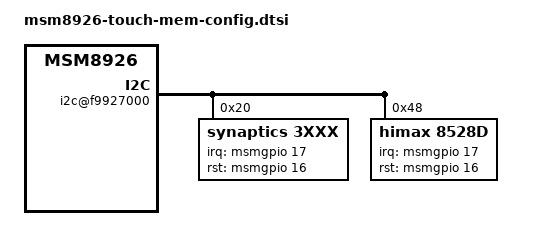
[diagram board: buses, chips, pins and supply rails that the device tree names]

/* Copyright (c) 2013, The Linux Foundation. All rights reserved.
 *
 * This program is free software; you can redistribute it and/or modify
 * it under the terms of the GNU General Public License version 2 and
 * only version 2 as published by the Free Software Foundation.
 *
 * This program is distributed in the hope that it will be useful,
 * but WITHOUT ANY WARRANTY; without even the implied warranty of
 * MERCHANTABILITY or FITNESS FOR A PARTICULAR PURPOSE.  See the
 * GNU General Public License for more details.
 */

&soc {
	i2c@f9927000 { /* BLSP1 QUP5 */
		synaptics@20 {
			compatible               = "synaptics,3xxx";
			reg                      = <0x20>;
			interrupt-parent         = <&msmgpio>;
			interrupts               = <17 0x2>;
			synaptics,panel-coords   = <0 1080 0 1920>;
			synaptics,display-coords = <0 720 0 1280>;
			synaptics,irq-gpio       = <&msmgpio 17 0x00>;
			synaptics,rst-gpio       = <&msmgpio 16 0x00>;
			synaptics,i2c_err_hlr    = <1>;
			tw_pin_mask              = <0x88>;
			report_type              = <1>;


			config0 {	//semi main  08
				default_cfg   = <1>;
				syn,pl-coords   = <0 1080 0 1920>;
				pr_number     = <1558441>;
				sensor_id     = <0x08>;
				config = [
					5A 41 52 41 00 7F 03 1E
					05 09 00 01 01 00 10 38
					04 80 07 1E 05 50 A5 18
					33 03 01 21 01 21 01 D7
					5D C1 5A 7C B3 B4 B4 00
					A0 00 00 00 00 09 04 AD
					0A 11 0A 78 07 F4 C8 DC
					42 2A 05 00 00 00 00 4C
					6C 74 3C 32 00 00 00 4C
					6C 74 1E 05 00 02 40 01
					80 03 0E 1F 12 3E 00 13
					04 1B 00 64 40 60 60 68
					48 48 40 40 40 2A 2A 29
					27 26 25 24 23 00 00 00
					00 00 00 00 02 00 E8 FD
					00 64 00 C8 00 80 0A 00
					B8 0B 00 C0 80 02 02 02
					02 02 02 02 02 20 20 20
					20 20 20 20 10 5E 61 63
					66 69 6C 6F 39 00 B4 00
					10 0A 00 00 00 02 04 07
					0A 0D 10 11 00 31 04 00
					00 00 00 00 00 00 00 00
					00 04 00 00 FF FF FF FF
					FF FF FF FF FF FF FF FF
					FF FF FF FF 51 51 51 51
					51 51 51 51 CD 0D 04 01
					14 1A 12 1B 13 19 16 18
					15 17 11 FF FF FF 0C 01
					10 13 11 0D 0A 08 03 02
					06 07 0E 0B 12 05 04 09
					0F FF 00 10 00 10 00 10
					00 10 80 80 80 80 80 80
					80 80 80 80 80 80 80 80
					80 80 80 80 80 80 80 80
					80 80 80 80 80 80 80 80
					80 80 80 80 00 19 03 02
					36 3C 08 B4 38 20 0A 82
					14 64 03 07 02 01 0C
				];
			};
			config1 {	//semi sec  88
				default_cfg   = <1>;
				syn,pl-coords   = <0 1080 0 1920>;
				pr_number     = <1558441>;
				sensor_id     = <0x88>;
				config = [
					5A 41 52 41 00 7F 03 1E
					05 09 00 01 01 00 10 38
					04 80 07 1E 05 50 A5 18
					33 03 01 21 01 21 01 D7
					5D C1 5A 7C B3 B4 B4 00
					A0 00 00 00 00 09 04 AD
					0A 11 0A 78 07 F4 C8 DC
					42 2A 05 00 00 00 00 4C
					6C 74 3C 32 00 00 00 4C
					6C 74 1E 05 00 02 40 01
					80 03 0E 1F 12 3E 00 13
					04 1B 00 64 40 60 60 68
					48 48 40 40 40 2A 2A 29
					27 26 25 24 23 00 00 00
					00 00 00 00 02 00 E8 FD
					00 64 00 C8 00 80 0A 00
					B8 0B 00 C0 80 02 02 02
					02 02 02 02 02 20 20 20
					20 20 20 20 10 5E 61 63
					66 69 6C 6F 39 00 B4 00
					10 0A 00 00 00 02 04 07
					0A 0D 10 11 00 31 04 00
					00 00 00 00 00 00 00 00
					00 04 00 00 FF FF FF FF
					FF FF FF FF FF FF FF FF
					FF FF FF FF 51 51 51 51
					51 51 51 51 CD 0D 04 01
					14 1A 12 1B 13 19 16 18
					15 17 11 FF FF FF 0C 01
					10 13 11 0D 0A 08 03 02
					06 07 0E 0B 12 05 04 09
					0F FF 00 10 00 10 00 10
					00 10 80 80 80 80 80 80
					80 80 80 80 80 80 80 80
					80 80 80 80 80 80 80 80
					80 80 80 80 80 80 80 80
					80 80 80 80 00 19 03 02
					36 3C 08 B4 38 20 0A 82
					14 64 03 07 02 01 0C
				];
			};

			config2 {	//panasonic
				default_cfg   = <1>;
				syn,pl-coords   = <0 1080 0 1920>;
				pr_number     = <1558441>;
				sensor_id     = <0x00>;
				config = [
                                33 32 00 05 00 7F 03 1E 05 08 00 01
                                01 00 10 38 04 80 07 1E 05 50 7E 3C
                                4F 02 01 1B 01 1C 01 EE 53 D9 51 36
                                B8 99 AC 00 A0 00 00 00 00 0A 04 C0
                                0B 13 0A 64 07 66 64 C0 43 2A 05 00
                                00 00 00 4C 6C 74 3C 32 00 00 00 4C
                                6C 74 1E 05 00 02 77 01 80 03 0E 1F
                                13 4B 00 13 04 1B 00 10 28 60 48 40
                                48 40 48 40 28 28 27 26 25 24 23 22
                                21 00 00 00 00 00 00 00 02 00 E8 FD
                                00 64 00 4A 01 80 0A 00 B8 0B 00 C0
                                80 02 02 02 02 02 02 05 02 20 20 10
                                10 10 10 40 10 6B 6F 39 3B 3D 3F 68
                                43 00 B4 00 10 28 00 00 00 03 06 0A
                                0E 12 16 18 00 31 04 00 00 00 00 00
                                00 00 00 00 00 00 00 00 FF FF FF FF
                                FF FF FF FF FF FF FF FF FF FF FF FF
                                51 51 51 51 51 51 51 51 CD 0D 04 01
                                17 15 18 16 19 13 1B 12 1A 14 11 FF
                                FF FF 0C 01 10 13 11 0D 0A 08 0F 03
                                02 06 07 0E 0B 12 05 04 09 FF 00 10
                                00 10 00 10 00 10 80 80 80 80 80 80
                                80 80 80 80 80 80 80 80 80 80 80 80
                                80 80 80 80 80 80 80 80 80 80 80 80
                                80 80 80 80 00 0F 01 02 36 3C 04 C4
                                20 20 00 91 14 60 03 06 28 01 00
				];
			};

			config3 {	//real second 80
				default_cfg   = <1>;
				syn,pl-coords   = <0 1080 0 1920>;
				pr_number     = <1558441>;
				sensor_id     = <0x80>;
				config = [
					33 32 00 03 00 7F 03 1E
					05 08 00 19 19 00 10 38
					04 80 07 1E 05 50 7E 3C
					4F 02 01 1B 01 1C 01 EE
					53 D9 51 36 B8 99 AC 00
					A0 00 00 00 00 0A 04 C0
					0B 13 0A 64 07 66 64 C0
					43 2A 05 00 00 00 00 4C
					6C 74 3C 32 00 00 00 4C
					6C 74 1E 05 00 02 77 01
					80 03 0E 1F 13 4B 00 13
					04 1B 00 10 28 60 48 40
					48 40 48 40 28 28 27 26
					25 24 23 22 21 00 00 00
					00 00 00 00 02 00 E8 FD
					00 64 00 4A 01 80 0A 00
					B8 0B 00 C0 80 02 02 02
					02 02 02 05 02 20 20 10
					10 10 10 40 10 6B 6F 39
					3B 3D 3F 68 43 00 B4 00
					10 28 00 00 00 03 06 0A
					0E 12 16 18 00 31 04 00
					00 00 00 00 00 00 00 00
					00 00 00 00 FF FF FF FF
					FF FF FF FF FF FF FF FF
					FF FF FF FF 51 51 51 51
					51 51 51 51 CD 0D 04 01
					17 15 18 16 19 13 1B 12
					1A 14 11 FF FF FF 0C 01
					10 13 11 0D 0A 08 0F 03
					02 06 07 0E 0B 12 05 04
					09 FF 00 10 00 10 00 10
					00 10 80 80 80 80 80 80
					80 80 80 80 80 80 80 80
					80 80 80 80 80 80 80 80
					80 80 80 80 80 80 80 80
					80 80 80 80 00 0F 01 02
					36 3C 04 84 10 20 00 91
					14 60 03 06 28 01 00
				];
			};
			config4 {	//MFG
				default_cfg   = <1>;
				syn,pl-coords   = <0 1080 0 1920>;
				pr_number     = <1293984>;
				config = [
					4D 45 4D 00 00 7F 03 1E
					05 08 00 19 19 00 10 38
					04 80 07 02 14 1E 05 50
					7E 3C 4F 02 01 3C 1B 01
					1C 01 EE 53 D9 51 36 B8
					99 AC 00 A0 00 00 00 00
					0A 04 C0 00 00 00 00 00
					00 19 01 00 0A 0B 13 0A
					00 14 0A 40 64 07 66 64
					C0 43 2A 05 00 00 00 00
					4C 6C 74 3C 32 00 00 00
					4C 6C 74 1E 05 00 02 77
					01 80 03 0E 1F 13 4B 00
					13 04 1B 00 10 28 60 48
					40 48 48 40 48 20 28 27
					26 25 24 23 22 21 00 00
					00 00 00 00 00 02 00 E8
					FD 00 64 00 4A 01 80 0A
					00 B8 0B 00 C0 80 02 02
					02 02 02 02 05 02 20 20
					10 10 10 10 40 10 6B 6F
					39 3B 3D 3F 68 43 00 B4
					00 10 28 00 00 00 03 06
					0A 0E 12 16 18 00 31 04
					00 00 00 00 00 00 00 00
					00 00 04 00 00 FF FF FF
					FF FF FF FF FF FF FF FF
					FF FF FF FF FF 51 51 51
					51 51 51 51 51 CD 0D 04
					01 17 15 18 16 19 13 1B
					12 1A 14 11 FF FF FF 0C
					01 10 13 11 0D 0A 08 0F
					03 02 06 07 0E 0B 12 05
					04 09 FF 00 10 00 10 00
					10 00 10 80 80 80 80 80
					80 80 80 80 80 80 80 80
					80 80 80 80 80 80 80 80
					80 80 80 80 80 80 80 80
					80 80 80 80 80 00 0F 01
					83 60
				];
			};

		};

		himax@48 {
		compatible               	= "himax,8528d";
		reg                      		= <0x48>;
		interrupt-parent         	= <&msmgpio>;
		interrupts               	= <17 0x2>;
		himax,panel-coords   	= <0 1080 0 1920>;
		himax,display-coords 	= <0 720 0 1280>;
		himax,irq-gpio       	= <&msmgpio 17 0x00>;
		himax,rst-gpio       	= <&msmgpio 16 0x00>;
		report_type              	= <1>;

		config0 {	//Panasonic
			sensor_id   	= <0x22>;
			himax,tw-coords   	= <0 1080 0 1920>;
			himax,pl-coords 	= <0 720 0 1280>;
			fw_ver     	= <0xC1>;
			c1 =[37 FF 08 FF 08];
			c2 =[3F 00];
			c3 =[62 00 00 10 03 00 00 00 00 11 11];
			c4 =[63 00 00 10 03 00 00 00 00 11 11];
			c5 =[64 02 00 12 00 00 00 00 00 11 21];
			c6 =[65 02 00 12 00 00 00 00 00 22 22];
			c7 =[66 02 00 12 00 00 00 00 00 22 22];
			c8 =[67 02 00 12 00 00 00 00 00 22 22];
			c9 =[68 00 00 30 01 00 00 00 00 22 22];
			c10 =[69 00 00 30 01 00 00 00 00 12 00];
			c11 =[6A 02 00 32 00 00 00 00 00 00 00];
			c12 =[6B 02 00 02 03 00 00 00 00 00 00];
			c13 =[6C 02 00 02 03 00 00 00 00 00 00];
			c14 =[6D 01 00 01 03 00 00 00 00 00 00];
			c15 =[6E 01 00 31 00 00 00 00 00 00 00];
			c16 =[6F 01 00 01 03 00 00 00 00 00 00];
			c17 =[70 01 00 21 00 00 00 00 00 00 00];
			c18 =[7B 03];
			c19 =[7C 00 D8 0C];
			c20 =[7F 00 04 0A 0A 04 00 00 00];
			c21 =[A4 94 62 94 86];
			c22 =[B4 05 01 03 03 03 04 0F 04 07 04
				  07 04 07 08];
			c23 =[B9 01 36];
			c24 =[BA 00];
			c25 =[BB 00];
			c26 =[BC 00 00 00 00];
			c27 =[BD 04 0C];
			c28 =[C2 10 00 00 00 00 00 00 00];
			c29 =[C5 0B 1D 00 10 1C 1E 0B 1D 08 16];
			c30 =[C6 14 10 1A];
			c31 =[C9 00 00 00 04 02 2B 27 2A 07 20
				  28 1F 25 08 2C 29 26 1E 05 03
				  01 06 00 00 00 00 00 00 00 00
				  00 00 00 00 00 00 00 00 00 00
				  00 00 00 00 00 00 00 00 00 00
				  00 00 00 00 00 00 00 00 00 00
				  00 00 00 00];
			c32 =[CB 01 F5 FF FF 01 00 05 00 5F 00
				  00 00];
			c33 =[D0 06 01];
			c34 =[D3 06 01];
			c35 =[D5 29 00 00 00 00 00 00 00 00 00
				  00 00 00 00 00 00];
			c36 =[40 02 5A
				  5F 00 F0 10 00 00
				  38 0E 0B 0F 0A 0A 0A 0C 0C 0C
				  30 26 40 40 36 00 00 00 00 05
				  10 20];
			c37 =[40 94 08 80 83 A6 00
				  48 24 0A 12 83 3C 00 00
				  11 00 41 42
				  0F 28 00 12 00 00
				  10 02 3C 64 00 00];
			c38 =[40 18 4F 4F 02 14 00 00 00
				  04 06 24 05 05 00 00 00];
			c39 =[40 30 40 05 00 00 D8 0C 00 00 02
				  03 80 00 00 00 00
				  10 02 80 00 00 00 00 0C];
			c40 =[40 00 00 00 00 00 00 00 00
				  A0 82 2D 01
				  0B 13 A0 13
				  00 00 04 38 07 80];
			c41 =[40 09 B6 12 34 79 12 0A 01 9B 05
				  6C 71 69 0C
				  0D 1F 18 9B 80 67 00 02 4F 07
				  CB 76 4C 00];
			c42 =[40 00 00 00 00 00 00 00 00];
			c43_1 =[40 1A FF 1B FF 0D FF 17 FF 18 03
				     FF FF 0B 00 FF FF 16 02 FF FF
				     1C 04 FF FF 15 FF 1D FF 0C FF
				     12];
			c43_2 =[40 FF FF 08 11 FF FF 06 19 FF
				     FF 0A 10 FF 07 FF 13 FF 05 FF
				     0F FF 09 FF 0E FF 01 14 FF FF];
			c44_1 =[40 A3 00 20 00 13 1E 32 00 00 00
				     00 00 00 00 00 00 00 00 00 00
				     00 00 00 00 00 00 00 00 00 00
				     56];
			c44_2 =[40 02 12 02 00 04];
			c45   =[40 00 00];
			};

		config1 {	//LGIT
			sensor_id   	= <0x12>;
			himax,tw-coords   	= <0 1080 0 1920>;
			himax,pl-coords 	= <0 720 0 1280>;
			fw_ver     	= <0xC1>;
			c1 =[37 FF 08 FF 08];
			c2 =[3F 00];
			c3 =[62 00 00 10 03 00 00 00 00 11 11];
			c4 =[63 00 00 10 03 00 00 00 00 11 11];
			c5 =[64 02 00 12 00 00 00 00 00 11 21];
			c6 =[65 02 00 12 00 00 00 00 00 22 22];
			c7 =[66 02 00 12 00 00 00 00 00 22 22];
			c8 =[67 02 00 12 00 00 00 00 00 22 22];
			c9 =[68 00 00 30 01 00 00 00 00 22 22];
			c10 =[69 00 00 30 01 00 00 00 00 11 00];
			c11 =[6A 02 00 32 00 00 00 00 00 00 00];
			c12 =[6B 02 00 02 03 00 00 00 00 00 00];
			c13 =[6C 02 00 02 03 00 00 00 00 00 00];
			c14 =[6D 01 00 01 03 00 00 00 00 00 00];
			c15 =[6E 01 00 31 00 00 00 00 00 00 00];
			c16 =[6F 01 00 01 03 00 00 00 00 00 00];
			c17 =[70 01 00 21 00 00 00 00 00 00 00];
			c18 =[7B 03];
			c19 =[7C 00 D8 0C];
			c20 =[7F 00 04 0A 0A 04 00 00 00];
			c21 =[A4 94 62 94 86];
			c22 =[B4 05 01 03 03 03 04 0F 04 07 04
			          07 04 07 08];
			c23 =[B9 01 36];
			c24 =[BA 00];
			c25 =[BB 00];
			c26 =[BC 00 00 00 00];
			c27 =[BD 04 0C];
			c28 =[C2 10 00 00 00 00 00 00 00];
			c29 =[C5 0B 1E 00 10 1B 1E 0B 1E 08 16];
			c30 =[C6 16 10 1A];
			c31 =[C9 00 00 00 04 02 2B 27 2A 07 20
					28 1F 25 08 2C 29 26 1E 05 03
					01 06 00 00 00 00 00 00 00 00
					00 00 00 00 00 00 00 00 00 00
					00 00 00 00 00 00 00 00 00 00
					00 00 00 00 00 00 00 00 00 00
					00 00 00 00];
			c32 =[CB 01 F5 FF FF 01 00 05 00 5F 00
			               00 00];
			c33 =[D0 06 01];
			c34 =[D3 06 01];
			c35 =[D5 29 00 00 00 00 00 00 00 00 00
			               00 00 00 00 00 00];
			c36 =[40 22 5A
			               5F 00 F0 10 00 00
			               38 0E 0B 0F 0A 0A 0A 0C 0C 0C
			               30 26 40 40 36 00 00 00 00 05
			               10 20];
			c37 =[40 94 08 80 83 A6 00
			               48 24 0A 12 83 3C 00 00
			               11 00 41 42
			               0F 28 00 12 00 00
			               10 02 3C 64 00 00];
			c38 =[40 18 4F 4F 02 14 00 00 00
			               04 06 24 05 05 00 00 00];
			c39 =[40 30 40 05 00 00 D8 0C 00 00 02
			               03 80 00 00 00 00
			               10 02 80 00 00 00 00 0C];
			c40 =[40 00 00 00 00 00 00 00 00
			               A0 82 2D 00
			               0B 13 A0 13
			               00 00 04 38 07 80];
			c41 =[40 09 B6 12 34 79 12 0A 01 9B 05
			               6C 71 69 0C
			               0D 1F 18 9B 80 67 00 02 4F 07
			               CB 76 4C 00];
			c42 =[40 00 00 00 00 00 00 00 00];

			c43_1 =[40 1A FF 1B FF 0D FF 17 FF 18 03
			                 FF FF 0B 00 FF FF 16 02 FF FF
			                 1C 04 FF FF 15 FF 1D FF 0C FF
			                 12];
			c43_2 =[40       FF FF 08 11 FF FF 06 19 FF
			                 FF 0A 10 FF 07 FF 13 FF 05 FF
			                 0F FF 09 FF 0E FF 01 14 FF FF];
			c44_1 =[40 A3 00 20 00 13 1E 32 00 00 00
			                 00 00 00 00 00 00 00 00 00 00
			                 00 00 00 00 00 00 00 00 00 00
			                 56];
			c44_2 =[40 02 12 02 00 04];
			c45   =[40 00 00];
			};

		config2 {	//Panasonic
			sensor_id   	= <0x21>;
			himax,tw-coords   	= <0 1080 0 1920>;
			himax,pl-coords 	= <0 720 0 1280>;
			fw_ver     	= <0xC1>;
			c1 =[37 FF 08 FF 08];
			c2 =[3F 00];
			c3 =[62 00 00 10 03 00 00 00 00 11 11];
			c4 =[63 00 00 10 03 00 00 00 00 11 11];
			c5 =[64 02 00 12 00 00 00 00 00 11 21];
			c6 =[65 02 00 12 00 00 00 00 00 22 22];
			c7 =[66 02 00 12 00 00 00 00 00 22 22];
			c8 =[67 02 00 12 00 00 00 00 00 22 22];
			c9 =[68 00 00 30 01 00 00 00 00 22 22];
			c10 =[69 00 00 30 01 00 00 00 00 12 00];
			c11 =[6A 02 00 32 00 00 00 00 00 00 00];
			c12 =[6B 02 00 02 03 00 00 00 00 00 00];
			c13 =[6C 02 00 02 03 00 00 00 00 00 00];
			c14 =[6D 01 00 01 03 00 00 00 00 00 00];
			c15 =[6E 01 00 31 00 00 00 00 00 00 00];
			c16 =[6F 01 00 01 03 00 00 00 00 00 00];
			c17 =[70 01 00 21 00 00 00 00 00 00 00];
			c18 =[7B 03];
			c19 =[7C 00 D8 0C];
			c20 =[7F 00 04 0A 0A 04 00 00 00];
			c21 =[A4 94 62 94 86];
			c22 =[B4 05 01 03 03 03 04 0F 04 07 04
				  07 04 07 08];
			c23 =[B9 01 36];
			c24 =[BA 00];
			c25 =[BB 00];
			c26 =[BC 00 00 00 00];
			c27 =[BD 04 0C];
			c28 =[C2 10 00 00 00 00 00 00 00];
			c29 =[C5 0B 1D 00 10 1C 1E 0B 1D 08 16];
			c30 =[C6 14 10 1A];
			c31 =[C9 00 00 00 04 02 2B 27 2A 07 20
				  28 1F 25 08 2C 29 26 1E 05 03
				  01 06 00 00 00 00 00 00 00 00
				  00 00 00 00 00 00 00 00 00 00
				  00 00 00 00 00 00 00 00 00 00
				  00 00 00 00 00 00 00 00 00 00
				  00 00 00 00];
			c32 =[CB 01 F5 FF FF 01 00 05 00 5F 00
				  00 00];
			c33 =[D0 06 01];
			c34 =[D3 06 01];
			c35 =[D5 29 00 00 00 00 00 00 00 00 00
				  00 00 00 00 00 00];
			c36 =[40 02 5A
				  5F 00 F0 10 00 00
				  38 0E 0B 0F 0A 0A 0A 0C 0C 0C
				  30 26 40 40 36 00 00 00 00 05
				  10 20];
			c37 =[40 94 08 80 83 A6 00
				  48 24 0A 12 83 3C 00 00
				  11 00 41 42
				  0F 28 00 12 00 00
				  10 02 3C 64 00 00];
			c38 =[40 18 4F 4F 02 14 00 00 00
				  04 06 24 05 05 00 00 00];
			c39 =[40 30 40 05 00 00 D8 0C 00 00 02
				  03 80 00 00 00 00
				  10 02 80 00 00 00 00 0C];
			c40 =[40 00 00 00 00 00 00 00 00
				  A0 82 2D 01
				  0B 13 A0 13
				  00 00 04 38 07 80];
			c41 =[40 09 B6 12 34 79 12 0A 01 9B 05
				  6C 71 69 0C
				  0D 1F 18 9B 80 67 00 02 4F 07
				  CB 76 4C 00];
			c42 =[40 00 00 00 00 00 00 00 00];
			c43_1 =[40 1A FF 1B FF 0D FF 17 FF 18 03
				     FF FF 0B 00 FF FF 16 02 FF FF
				     1C 04 FF FF 15 FF 1D FF 0C FF
				     12];
			c43_2 =[40 FF FF 08 11 FF FF 06 19 FF
				     FF 0A 10 FF 07 FF 13 FF 05 FF
				     0F FF 09 FF 0E FF 01 14 FF FF];
			c44_1 =[40 A3 00 20 00 13 1E 32 00 00 00
				     00 00 00 00 00 00 00 00 00 00
				     00 00 00 00 00 00 00 00 00 00
				     56];
			c44_2 =[40 02 12 02 00 04];
			c45   =[40 00 00];
			};

		config3 {	//LGIT
			sensor_id   	= <0x11>;
			himax,tw-coords   	= <0 1080 0 1920>;
			himax,pl-coords 	= <0 720 0 1280>;
			fw_ver     	= <0xC1>;
			c1 =[37 FF 08 FF 08];
			c2 =[3F 00];
			c3 =[62 00 00 10 03 00 00 00 00 11 11];
			c4 =[63 00 00 10 03 00 00 00 00 11 11];
			c5 =[64 02 00 12 00 00 00 00 00 11 21];
			c6 =[65 02 00 12 00 00 00 00 00 22 22];
			c7 =[66 02 00 12 00 00 00 00 00 22 22];
			c8 =[67 02 00 12 00 00 00 00 00 22 22];
			c9 =[68 00 00 30 01 00 00 00 00 22 22];
			c10 =[69 00 00 30 01 00 00 00 00 11 00];
			c11 =[6A 02 00 32 00 00 00 00 00 00 00];
			c12 =[6B 02 00 02 03 00 00 00 00 00 00];
			c13 =[6C 02 00 02 03 00 00 00 00 00 00];
			c14 =[6D 01 00 01 03 00 00 00 00 00 00];
			c15 =[6E 01 00 31 00 00 00 00 00 00 00];
			c16 =[6F 01 00 01 03 00 00 00 00 00 00];
			c17 =[70 01 00 21 00 00 00 00 00 00 00];
			c18 =[7B 03];
			c19 =[7C 00 D8 0C];
			c20 =[7F 00 04 0A 0A 04 00 00 00];
			c21 =[A4 94 62 94 86];
			c22 =[B4 05 01 03 03 03 04 0F 04 07 04
			          07 04 07 08];
			c23 =[B9 01 36];
			c24 =[BA 00];
			c25 =[BB 00];
			c26 =[BC 00 00 00 00];
			c27 =[BD 04 0C];
			c28 =[C2 10 00 00 00 00 00 00 00];
			c29 =[C5 0B 1E 00 10 1B 1E 0B 1E 08 16];
			c30 =[C6 16 10 1A];
			c31 =[C9 00 00 00 04 02 2B 27 2A 07 20
					28 1F 25 08 2C 29 26 1E 05 03
					01 06 00 00 00 00 00 00 00 00
					00 00 00 00 00 00 00 00 00 00
					00 00 00 00 00 00 00 00 00 00
					00 00 00 00 00 00 00 00 00 00
					00 00 00 00];
			c32 =[CB 01 F5 FF FF 01 00 05 00 5F 00
			               00 00];
			c33 =[D0 06 01];
			c34 =[D3 06 01];
			c35 =[D5 29 00 00 00 00 00 00 00 00 00
			               00 00 00 00 00 00];
			c36 =[40 22 5A
			               5F 00 F0 10 00 00
			               38 0E 0B 0F 0A 0A 0A 0C 0C 0C
			               30 26 40 40 36 00 00 00 00 05
			               10 20];
			c37 =[40 94 08 80 83 A6 00
			               48 24 0A 12 83 3C 00 00
			               11 00 41 42
			               0F 28 00 12 00 00
			               10 02 3C 64 00 00];
			c38 =[40 18 4F 4F 02 14 00 00 00
			               04 06 24 05 05 00 00 00];
			c39 =[40 30 40 05 00 00 D8 0C 00 00 02
			               03 80 00 00 00 00
			               10 02 80 00 00 00 00 0C];
			c40 =[40 00 00 00 00 00 00 00 00
			               A0 82 2D 00
			               0B 13 A0 13
			               00 00 04 38 07 80];
			c41 =[40 09 B6 12 34 79 12 0A 01 9B 05
			               6C 71 69 0C
			               0D 1F 18 9B 80 67 00 02 4F 07
			               CB 76 4C 00];
			c42 =[40 00 00 00 00 00 00 00 00];

			c43_1 =[40 1A FF 1B FF 0D FF 17 FF 18 03
			                 FF FF 0B 00 FF FF 16 02 FF FF
			                 1C 04 FF FF 15 FF 1D FF 0C FF
			                 12];
			c43_2 =[40       FF FF 08 11 FF FF 06 19 FF
			                 FF 0A 10 FF 07 FF 13 FF 05 FF
			                 0F FF 09 FF 0E FF 01 14 FF FF];
			c44_1 =[40 A3 00 20 00 13 1E 32 00 00 00
			                 00 00 00 00 00 00 00 00 00 00
			                 00 00 00 00 00 00 00 00 00 00
			                 56];
			c44_2 =[40 02 12 02 00 04];
			c45   =[40 00 00];
			};
		};
	};
};
